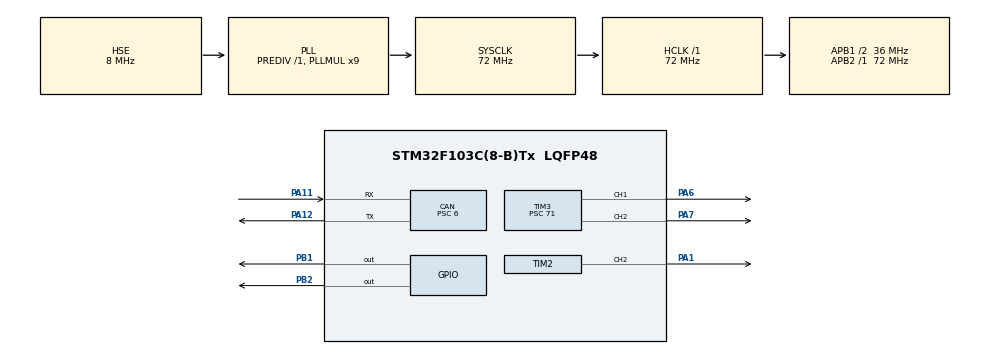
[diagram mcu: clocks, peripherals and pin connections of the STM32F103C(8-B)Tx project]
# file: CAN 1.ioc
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CAN.ABOM=DISABLE
CAN.BS1=CAN_BS1_3TQ
CAN.BS2=CAN_BS2_2TQ
CAN.CalculateBaudRate=999999
CAN.CalculateTimeBit=1000
CAN.CalculateTimeQuantum=166.66666666666669
CAN.Mode=CAN_MODE_NORMAL
CAN.NART=ENABLE
CAN.Prescaler=6
CAN.RFLM=DISABLE
Mcu.Family=STM32F1
Mcu.Name=STM32F103C(8-B)Tx
Mcu.Package=LQFP48
NVIC.PriorityGroup=NVIC_PRIORITYGROUP_4
NVIC.TIM3_IRQn=true\:0\:0\:false\:false\:true\:true\:true\:true
NVIC.USB_LP_CAN1_RX0_IRQn=true\:1\:0\:true\:false\:true\:true\:true\:true
PA1.Signal=S_TIM2_CH2
PA11.Mode=CAN_Activate
PA11.Signal=CAN_RX
PA12.Mode=CAN_Activate
PA12.Signal=CAN_TX
PA13.Mode=Serial_Wire
PA13.Signal=SYS_JTMS-SWDIO
PA14.Mode=Serial_Wire
PA14.Signal=SYS_JTCK-SWCLK
PA6.Signal=S_TIM3_CH1
PA7.Signal=S_TIM3_CH2
PB1.Signal=GPIO_Output
PB2.Signal=GPIO_Output
PD0-OSC_IN.Mode=HSE-External-Oscillator
PD0-OSC_IN.Signal=RCC_OSC_IN
PD1-OSC_OUT.Mode=HSE-External-Oscillator
PD1-OSC_OUT.Signal=RCC_OSC_OUT
ProjectManager.HeapSize=0x200
ProjectManager.StackSize=0x400
ProjectManager.TargetToolchain=MDK-ARM V5.32
RCC.AHBFreq_Value=72000000
RCC.APB1CLKDivider=RCC_HCLK_DIV2
RCC.APB1Freq_Value=36000000
RCC.APB1TimFreq_Value=72000000
RCC.APB2Freq_Value=72000000
RCC.APB2TimFreq_Value=72000000
RCC.HCLKFreq_Value=72000000
RCC.PLLMUL=RCC_PLL_MUL9
RCC.PLLSourceVirtual=RCC_PLLSOURCE_HSE
RCC.SYSCLKFreq_VALUE=72000000
RCC.SYSCLKSource=RCC_SYSCLKSOURCE_PLLCLK
RCC.USBFreq_Value=72000000
SH.S_TIM2_CH2.0=TIM2_CH2,PWM Generation2 CH2
SH.S_TIM3_CH1.0=TIM3_CH1,PWM Generation1 CH1
SH.S_TIM3_CH2.0=TIM3_CH2,PWM Generation2 CH2
TIM2.Channel-PWM\ Generation2\ CH2=TIM_CHANNEL_2
TIM2.OCPolarity_2=TIM_OCPOLARITY_LOW
TIM2.Period=999
TIM2.Prescaler=71
TIM3.Channel-PWM\ Generation1\ CH1=TIM_CHANNEL_1
TIM3.Channel-PWM\ Generation2\ CH2=TIM_CHANNEL_2
TIM3.OCPolarity_2=TIM_OCPOLARITY_LOW
TIM3.Period=999
TIM3.Prescaler=71
VP_TIM3_VS_ClockSourceINT.Mode=Internal
board=custom

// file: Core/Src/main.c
/* USER CODE BEGIN Header */
/**
  ******************************************************************************
  * @file           : main.c
  * @brief          : Main program body
  ******************************************************************************
  * @attention
  *
  * Copyright (c) 2023 STMicroelectronics.
  * All rights reserved.
  *
  * This software is licensed under terms that can be found in the LICENSE file
  * in the root directory of this software component.
  * If no LICENSE file comes with this software, it is provided AS-IS.
  *
  ******************************************************************************
  */
/* USER CODE END Header */
#include "main.h"
#include "can.h"
#include "tim.h"
#include "gpio.h"

/* USER CODE BEGIN Includes */
#include "M_CAN.h"
#include "pid2.h"
//#include "bsp_main.h"
//#include "pid2.h"
/* USER CODE END Includes */

/* USER CODE BEGIN PTD */
//static motor_t motor1;
//extern _motor_data motor_data;

/* USER CODE END PTD */

/* USER CODE BEGIN PD */
MOTOR_TypeDef motor;

_motor_data motor_data;

float err = 0;
/* USER CODE END PD */

/* USER CODE BEGIN PM */

//void HAL_TIM_PeriodElapsedCallback(TIM_HandleTypeDef *htim)  //��ʱ���жϻص�����
//{
//	int time_flag=0;

//	time_flag++;
//	if(time_flag%10==0)
//	{
//		motor1.actual_angle = motor_data.angle;
//		motor1.pid_speed.target_val = location_pid_realize(&motor1.pid_location, motor1.actual_angle);
//		motor1.actual_speed = motor_data.speed;
//		motor1.set_currunt = speed_pid_realize(&motor1.pid_speed, motor1.actual_speed);
//		CAN_Tx_Message(motor1.set_currunt);
//	}
//}
/* USER CODE END PM */

void SystemClock_Config(void);

int main(void)
{

  /* MCU Configuration--------------------------------------------------------*/

  /* Reset of all peripherals, Initializes the Flash interface and the Systick. */
  HAL_Init();

  /* Configure the system clock */
  SystemClock_Config();

  /* Initialize all configured peripherals */
  MX_GPIO_Init();
  MX_CAN_Init();
  MX_TIM3_Init();
  MX_TIM2_Init();
  /* USER CODE BEGIN 2 */

//	HAL_TIM_PWM_Start(&htim2,TIM_CHANNEL_2);
//	HAL_TIM_Base_Start_IT(&htim3);
//	main_init(&motor1);
		Bsp_canInit();
//	PID_param_init(&motor.PID_ANGLE,&motor.PID_ANGLE);
		PID_param_Init(&motor.PID_ANGLE,&motor.PID_SPEED);
		err = motor_data.real_angle;
  /* USER CODE END 2 */

  /* Infinite loop */
  /* USER CODE BEGIN WHILE */
  while (1)
  {
		Motor_Auto_Run();
//	CAN_Tx_Message(6000);
		HAL_Delay(2);

    /* USER CODE END WHILE */

  }
}

void SystemClock_Config(void)
{
  RCC_OscInitTypeDef RCC_OscInitStruct = {0};
  RCC_ClkInitTypeDef RCC_ClkInitStruct = {0};

  /** Initializes the RCC Oscillators according to the specified parameters
  * in the RCC_OscInitTypeDef structure.
  */
  RCC_OscInitStruct.OscillatorType = RCC_OSCILLATORTYPE_HSE;
  RCC_OscInitStruct.HSEState = RCC_HSE_ON;
  RCC_OscInitStruct.HSEPredivValue = RCC_HSE_PREDIV_DIV1;
  RCC_OscInitStruct.HSIState = RCC_HSI_ON;
  RCC_OscInitStruct.PLL.PLLState = RCC_PLL_ON;
  RCC_OscInitStruct.PLL.PLLSource = RCC_PLLSOURCE_HSE;
  RCC_OscInitStruct.PLL.PLLMUL = RCC_PLL_MUL9;
  if (HAL_RCC_OscConfig(&RCC_OscInitStruct) != HAL_OK)
  {
    Error_Handler();
  }

  /** Initializes the CPU, AHB and APB buses clocks
  */
  RCC_ClkInitStruct.ClockType = RCC_CLOCKTYPE_HCLK|RCC_CLOCKTYPE_SYSCLK
                              |RCC_CLOCKTYPE_PCLK1|RCC_CLOCKTYPE_PCLK2;
  RCC_ClkInitStruct.SYSCLKSource = RCC_SYSCLKSOURCE_PLLCLK;
  RCC_ClkInitStruct.AHBCLKDivider = RCC_SYSCLK_DIV1;
  RCC_ClkInitStruct.APB1CLKDivider = RCC_HCLK_DIV2;
  RCC_ClkInitStruct.APB2CLKDivider = RCC_HCLK_DIV1;

  if (HAL_RCC_ClockConfig(&RCC_ClkInitStruct, FLASH_LATENCY_2) != HAL_OK)
  {
    Error_Handler();
  }
}

void Error_Handler(void)
{
  __disable_irq();
  while (1)
  {
  }
}
